# ATmega64HVE2 register map
Vendor: Atmel; File version: 1.0
CPU: other r0p0, little endian, no MPU, no FPU, 4 interrupt priority bits
Registers are 8-bit, read-write, reset 0x0 unless marked. A register's access mark holds for its fields unless they carry their own. Offsets are from the block's base; [hi:lo] are bit positions.

## EEPROM
Base 0x0080003F
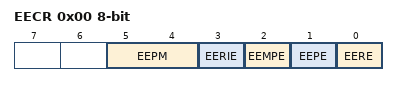
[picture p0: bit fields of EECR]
0x00 EECR — EEPROM Control Register
  [5:4] EEPM
    0=ERASE_AND_WRITE_IN_ONE_OPERATION; 1=ERASE_ONLY; 2=WRITE_ONLY
  [3] EERIE — EEProm Ready Interrupt Enable
  [2] EEMPE — EEPROM Master Write Enable
  [1] EEPE — EEPROM Write Enable
  [0] EERE — EEPROM Read Enable
0x01 EEDR — EEPROM Data Register
0x02 EEAR 16-bit (reset mask 0xFF) — EEPROM Read/Write Access

## EXINT — External Interrupts
Base 0x0080003B
0x00 PCIFR — Pin Change Interrupt Flag Register (read-only for debugger)
  [1:0] PCIF — Pin Change Interrupt Flags
0x01 EIFR — External Interrupt Flag Register (read-only for debugger)
  [0] INTF0 — External Interrupt Flag 0
0x02 EIMSK — External Interrupt Mask Register
  [0] INT0 — External Interrupt Request 0 Enable
0x2D PCICR — Pin Change Interrupt Control Register
  [1:0] PCIE — Pin Change Interrupt Enables
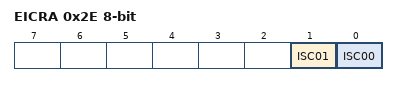
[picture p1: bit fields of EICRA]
0x2E EICRA — External Interrupt Control Register
  [1] ISC01 — External Interrupt Sense Control 0 Bit 1
  [0] ISC00 — External Interrupt Sense Control 0 Bit 0
    0=LOW_LEVEL_OF_INTX; 1=ANY_LOGICAL_CHANGE_OF_INTX
0x30 PCMSK0 — Pin Change Enable Mask Register 0
0x31 PCMSK1 — Pin Change Enable Mask Register 1

## FUSE — Fuses
Base 0x00800000
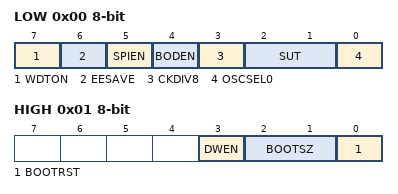
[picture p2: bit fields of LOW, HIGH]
0x00 LOW
  [7] WDTON — Watch-dog Timer always on
  [6] EESAVE — Preserve EEPROM through the Chip Erase cycle
  [5] SPIEN — Serial program downloading (SPI) enabled
  [4] BODEN — Brown-out detection enabled
  [3] CKDIV8 — Divide clock by 8
  [2:1] SUT — Select start-up time
    0=14CK_0MS (Start-up time 14 CK + 0 ms); 1=14CK_16MS (Start-up time 14 CK + 16 ms); 2=14CK_32MS (Start-up time 14 CK + 32 ms); 3=14CK_64MS (Start-up time 14 CK + 64 ms)
  [0] OSCSEL0 — Oscillator select
0x01 HIGH
  [3] DWEN — Debug Wire enable
  [2:1] BOOTSZ — Select Boot Size
    0=4096W_7000 (Boot Flash size=4096 words Boot address=$7000); 1=2048W_7800 (Boot Flash size=2048 words Boot address=$7800); 2=1024W_7C00 (Boot Flash size=1024 words Boot address=$7C00); 3=512W_7E00 (Boot Flash size=512 words Boot address=$7E00)
  [0] BOOTRST — Boot Reset vector Enabled

## LINUART — Local Interconnect Network
Base 0x008000C0
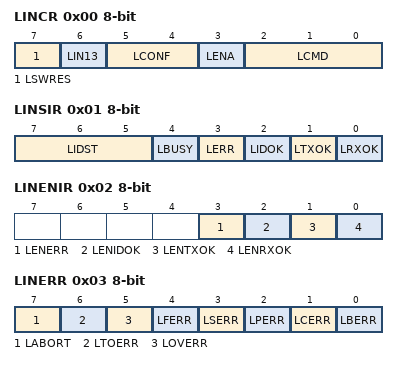
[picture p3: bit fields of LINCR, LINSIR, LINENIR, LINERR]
0x00 LINCR — LIN Control Register
  [7] LSWRES — Software Reset
  [6] LIN13 — LIN Standard
  [5:4] LCONF — LIN Configuration bits
  [3] LENA — LIN or UART Enable
  [2:0] LCMD — LIN Command and Mode bits
0x01 LINSIR — LIN Status and Interrupt Register
  [7:5] LIDST — Identifier Status bits
  [4] LBUSY — Busy Signal
  [3] LERR — Error Interrupt
  [2] LIDOK — Identifier Interrupt
  [1] LTXOK — Transmit Performed Interrupt
  [0] LRXOK — Receive Performed Interrupt
0x02 LINENIR — LIN Enable Interrupt Register
  [3] LENERR — Enable Error Interrupt
  [2] LENIDOK — Enable Identifier Interrupt
  [1] LENTXOK — Enable Transmit Performed Interrupt
  [0] LENRXOK — Enable Receive Performed Interrupt
0x03 LINERR — LIN Error Register (read-only for debugger)
  [7] LABORT — Abort Flag
  [6] LTOERR — Frame Time Out Error Flag
  [5] LOVERR — Overrun Error Flag
  [4] LFERR — Framing Error Flag
  [3] LSERR — Synchronization Error Flag
  [2] LPERR — Parity Error Flag
  [1] LCERR — Checksum Error Flag
  [0] LBERR — Bit Error Flag
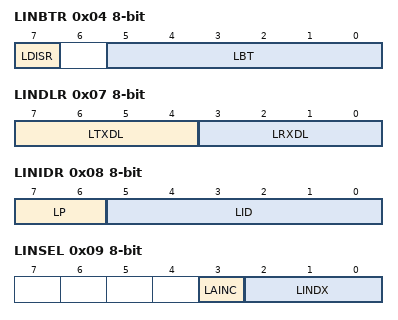
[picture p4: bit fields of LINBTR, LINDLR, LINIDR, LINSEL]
0x04 LINBTR — LIN Bit Timing Register
  [7] LDISR — Disable Bit Timing Resynchronization
  [5:0] LBT — LIN Bit Timing bits
0x05 LINBRRL — LIN Baud Rate Low Register
  [7:0] LDIV
0x06 LINBRRH — LIN Baud Rate High Register
  [3:0] LDIV
0x07 LINDLR — LIN Data Length Register
  [7:4] LTXDL — LIN Transmit Data Length bits
  [3:0] LRXDL — LIN Receive Data Length bits
0x08 LINIDR — LIN Identifier Register
  [7:6] LP — Parity bits
  [5:0] LID — Identifier bit 5 or Data Length bits
0x09 LINSEL — LIN Data Buffer Selection Register
  [3] LAINC — Auto Increment of Data Buffer Index (Active Low)
  [2:0] LINDX — FIFO LIN Data Buffer Index bits
0x0A LINDAT — LIN Data Register (write-only for debugger)
  [7:0] LDATA
